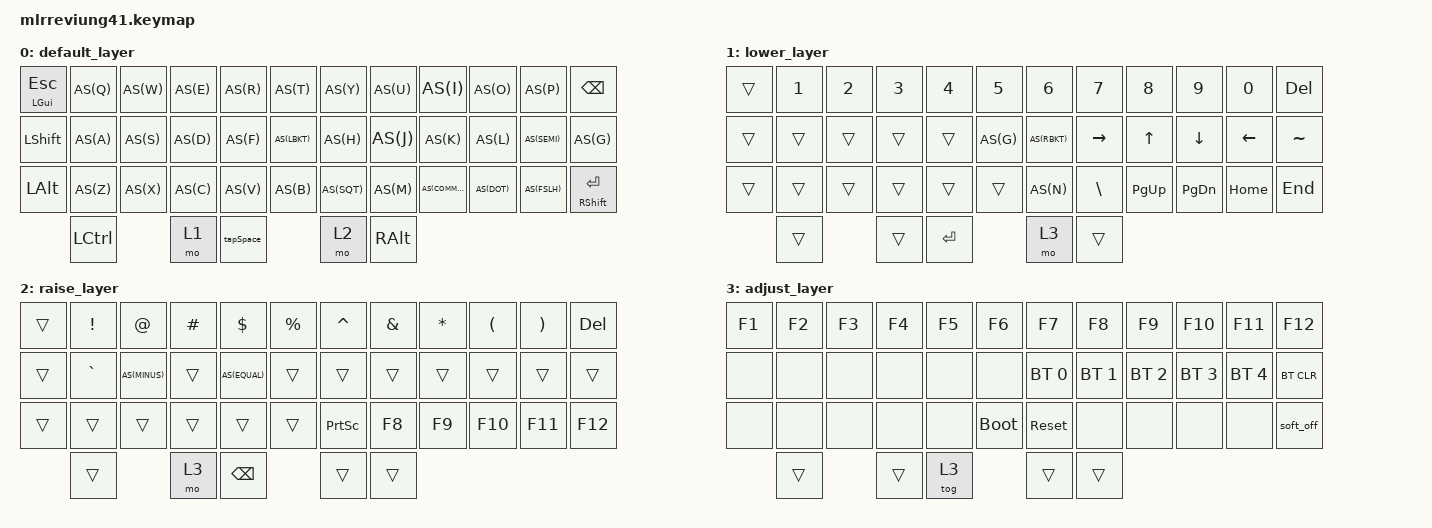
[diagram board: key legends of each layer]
/*
 * Copyright (c) 2020 The ZMK Contributors
 *
 * SPDX-License-Identifier: MIT
 */

#include <behaviors.dtsi>
#include <dt-bindings/zmk/keys.h>
#include <dt-bindings/zmk/bt.h>
// #include <dt-bindings/zmk/rgb.h>
#define AS(keycode) &as LS(keycode) keycode     // Autoshift Macro

/ {
        behaviors {
                as: auto_shift {
                        compatible = "zmk,behavior-hold-tap";
                        label = "AUTO_SHIFT";
                        #binding-cells = <2>;
                        tapping_term_ms = <160>;
                        quick_tap_ms = <0>;
                        flavor = "tap-preferred";
                        bindings = <&kp>, <&kp>;
                };
                tapSpace: tap_dance_0 {
                        compatible = "zmk,behavior-tap-dance";
                        label = "TAP_SPACE_TAB";
                        #binding-cells = <0>;
                        tapping-term-ms = <230>;
                        bindings = <&kp SPACE>, <&kp TAB>;
                };
        };

        keymap {
                compatible = "zmk,keymap";

                default_layer {
// -------------------------------------------------------------------------------------
// |  TAB |  Q  |  W  |  E  |  R  |  T  |   |  Y  |  U   |  I  |  O  |  P  |   BKSP    |
// | CTRL |  A  |  S  |  D  |  F  |  G  |   |  H  |  J   |  K  |  L  |  ;  |    '      |
// | SHFT |  Z  |  X  |  C  |  V  |  B  |   |  N  |  M   |  ,  |  .  |  /  | SHFT(RET) |
//                         | ALT | LWR | SPC | RSE  | ALT |
                        bindings = <
&mt LGUI ESC   AS(Q) AS(W) AS(E) AS(R) AS(T)    AS(Y)   AS(U) AS(I)     AS(O)   AS(P)    &kp BSPC     
&kp LSHFT AS(A) AS(S) AS(D) AS(F) AS(LBKT)      AS(H)   AS(J) AS(K)     AS(L)   AS(SEMI) AS(G)     
&kp LALT AS(Z) AS(X) AS(C) AS(V) AS(B)          AS(SQT) AS(M) AS(COMMA) AS(DOT) AS(FSLH) &mt RSHFT RET
                  &kp LCTRL  &mo 1 &tapSpace  &mo 2  &kp RALT
                        >;
                };

                lower_layer {
// ------------------------------------------------------------------------------------
// |    |  !  |  @  |  #  |  $  |  %  |   |  ^  |  &  |  *  |  (  |  )  |      DEL    |
// |    |  _  |  +  |  {  |  }  | "|" |   | LFT | DWN |  UP | RGT |  `  |       ~     |
// |    | ESC | GUI | ALT | CAPS|  "  |   | HOME| END | PGUP| PGDN| PRSC| SHFT(SPACE) |
//                       |     |     | RET | ADJ |     |
                        bindings = <
&trans &kp N1  &kp N2    &kp N3   &kp N4   &kp N5     &kp N6   &kp N7    &kp N8    &kp N9    &kp N0     &kp DEL
&trans &trans  &trans    &trans   &trans   AS(G)      AS(RBKT) &kp RIGHT &kp UP    &kp DOWN  &kp LEFT   &kp TILDE
&trans &trans  &trans    &trans   &trans   &trans     AS(N)    &kp BSLH  &kp PG_UP &kp PG_DN &kp HOME   &kp END
                        &trans    &trans       &kp ENTER      &mo 3       &trans
                        >;
                };

                raise_layer {
// ----------------------------------------------------------------------------
// |    |  1  |  2  |  3  |  4  |  5  |   |  6  |  7  |  8  |  9  |  0  | DEL |
// |    |  -  |  =  |  [  |  ]  |  \  |   | F1  | F2  | F3  | F4  | F5  | F6  |
// |    | ESC | GUI | ALT | CAPS|  "  |   | F7  | F8  | F9  | F10 | F11 | F12 |
//                       |     | ADJ | BKSP |    |     |
                        bindings = <
&trans &kp EXCL  &kp AT    &kp HASH &kp DLLR  &kp PRCNT   &kp CARET &kp AMPS &kp ASTRK &kp LPAR  &kp RPAR  &kp DEL
&trans &kp GRAVE AS(MINUS) &trans   AS(EQUAL) &trans      &trans    &trans   &trans    &trans    &trans    &trans
&trans &trans  &trans      &trans   &trans    &trans      &kp PRINTSCREEN    &kp F8    &kp F9    &kp F10   &kp F11   &kp F12
                             &trans      &mo 3       &kp BSPC        &trans      &trans
                        >;
                };

                adjust_layer {
// -----------------------------------------------------------------------------------------
// | RGB BRI+ | RGB SAT+ | RGB HUE+ | RGB ANI+ |    | RGB TOG |   |  BT1  | BT2 | BT3 | BT4 | BT5 | BT CLR |
// | RGB BRI- | RGB SAT- | RGB HUE- | RGB ANI- |    |         |   |       |     |     |     |     |        |
// |          |          |          |          |    |         |   | RESET |     |     |     |     |        |
//                                              |     |     |     |     |     |
                        bindings = <
&kp F1 &kp F2 &kp F3 &kp F4 &kp F5 &kp F6               &kp F7       &kp F8        &kp F9      &kp F10      &kp F11      &kp F12
&none  &none  &none  &none  &none  &none                &bt BT_SEL 0 &bt BT_SEL 1 &bt BT_SEL 2 &bt BT_SEL 3 &bt BT_SEL 4 &bt BT_CLR
&none  &none  &none  &none  &none  &bootloader          &sys_reset   &none        &none        &none        &none        &soft_off
                        &trans      &trans       &tog 3        &trans      &trans
                        >;
                };
        };
};
